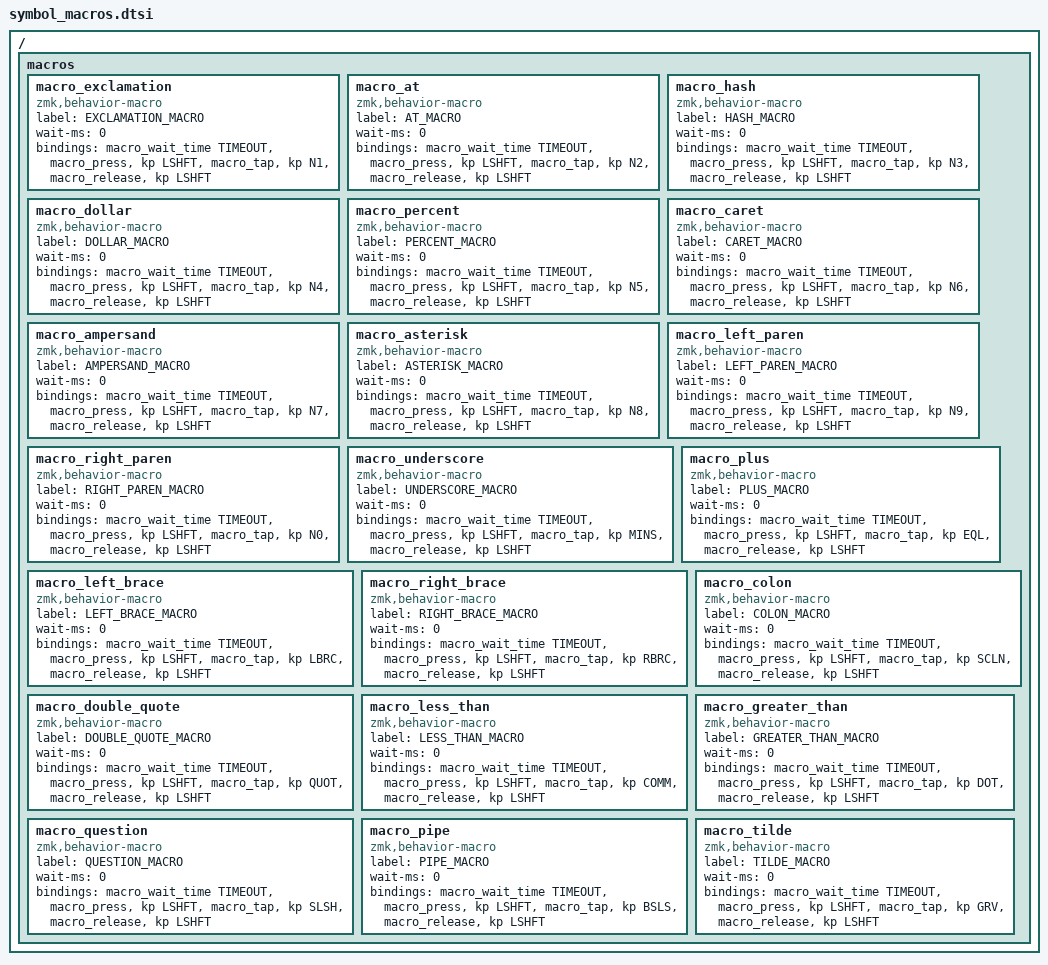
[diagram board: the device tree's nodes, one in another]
/ {
    macros {
        // ! : Shift + 1
        macro_exclamation: macro_exclamation {
            compatible = "zmk,behavior-macro";
            #binding-cells = <0>;
            label = "EXCLAMATION_MACRO";
            wait-ms = <0>; // 必要なら調整
            bindings = 
                <&macro_wait_time TIMEOUT>,
                <&macro_press &kp LSHFT>,
                <&macro_tap &kp N1>,
                <&macro_release &kp LSHFT>;
        };

        // @ : Shift + 2
        macro_at: macro_at {
            compatible = "zmk,behavior-macro";
            #binding-cells = <0>;
            label = "AT_MACRO";
            wait-ms = <0>;
            bindings = 
                <&macro_wait_time TIMEOUT>,
                <&macro_press &kp LSHFT>,
                <&macro_tap &kp N2>,
                <&macro_release &kp LSHFT>;
        };

        // # : Shift + 3
        macro_hash: macro_hash {
            compatible = "zmk,behavior-macro";
            #binding-cells = <0>;
            label = "HASH_MACRO";
            wait-ms = <0>;
            bindings = 
                <&macro_wait_time TIMEOUT>,
                <&macro_press &kp LSHFT>,
                <&macro_tap &kp N3>,
                <&macro_release &kp LSHFT>;
        };

        // $ : Shift + 4
        macro_dollar: macro_dollar {
            compatible = "zmk,behavior-macro";
            #binding-cells = <0>;
            label = "DOLLAR_MACRO";
            wait-ms = <0>;
            bindings = 
                <&macro_wait_time TIMEOUT>,
                <&macro_press &kp LSHFT>,
                <&macro_tap &kp N4>,
                <&macro_release &kp LSHFT>;
        };

        // % : Shift + 5
        macro_percent: macro_percent {
            compatible = "zmk,behavior-macro";
            #binding-cells = <0>;
            label = "PERCENT_MACRO";
            wait-ms = <0>;
            bindings = 
                <&macro_wait_time TIMEOUT>,
                <&macro_press &kp LSHFT>,
                <&macro_tap &kp N5>,
                <&macro_release &kp LSHFT>;
        };

        // ^ : Shift + 6
        macro_caret: macro_caret {
            compatible = "zmk,behavior-macro";
            #binding-cells = <0>;
            label = "CARET_MACRO";
            wait-ms = <0>;
            bindings =
                <&macro_wait_time TIMEOUT>,
                <&macro_press &kp LSHFT>,
                <&macro_tap &kp N6>,
                <&macro_release &kp LSHFT>;
        };

        // & : Shift + 7
        macro_ampersand: macro_ampersand {
            compatible = "zmk,behavior-macro";
            #binding-cells = <0>;
            label = "AMPERSAND_MACRO";
            wait-ms = <0>;
            bindings =
                <&macro_wait_time TIMEOUT>,
                <&macro_press &kp LSHFT>,
                <&macro_tap &kp N7>,
                <&macro_release &kp LSHFT>;
        };

        // * : Shift + 8
        macro_asterisk: macro_asterisk {
            compatible = "zmk,behavior-macro";
            #binding-cells = <0>;
            label = "ASTERISK_MACRO";
            wait-ms = <0>;
            bindings =
                <&macro_wait_time TIMEOUT>,
                <&macro_press &kp LSHFT>,
                <&macro_tap &kp N8>,
                <&macro_release &kp LSHFT>;
        };

        // ( : Shift + 9
        macro_left_paren: macro_left_paren {
            compatible = "zmk,behavior-macro";
            #binding-cells = <0>;
            label = "LEFT_PAREN_MACRO";
            wait-ms = <0>;
            bindings =
                <&macro_wait_time TIMEOUT>,
                <&macro_press &kp LSHFT>,
                <&macro_tap &kp N9>,
                <&macro_release &kp LSHFT>;
        };

        // ) : Shift + 0
        macro_right_paren: macro_right_paren {
            compatible = "zmk,behavior-macro";
            #binding-cells = <0>;
            label = "RIGHT_PAREN_MACRO";
            wait-ms = <0>;
            bindings =
                <&macro_wait_time TIMEOUT>,
                <&macro_press &kp LSHFT>,
                <&macro_tap &kp N0>,
                <&macro_release &kp LSHFT>;
        };

        // _ : Shift + - (MINS)
        macro_underscore: macro_underscore {
            compatible = "zmk,behavior-macro";
            #binding-cells = <0>;
            label = "UNDERSCORE_MACRO";
            wait-ms = <0>;
            bindings =
                <&macro_wait_time TIMEOUT>,
                <&macro_press &kp LSHFT>,
                <&macro_tap &kp MINS>,
                <&macro_release &kp LSHFT>;
        };

        // + : Shift + = (EQL)
        macro_plus: macro_plus {
            compatible = "zmk,behavior-macro";
            #binding-cells = <0>;
            label = "PLUS_MACRO";
            wait-ms = <0>;
            bindings =
                <&macro_wait_time TIMEOUT>,
                <&macro_press &kp LSHFT>,
                <&macro_tap &kp EQL>,
                <&macro_release &kp LSHFT>;
        };

        // { : Shift + [ (LBRC)
        macro_left_brace: macro_left_brace {
            compatible = "zmk,behavior-macro";
            #binding-cells = <0>;
            label = "LEFT_BRACE_MACRO";
            wait-ms = <0>;
            bindings =
                <&macro_wait_time TIMEOUT>,
                <&macro_press &kp LSHFT>,
                <&macro_tap &kp LBRC>,
                <&macro_release &kp LSHFT>;
        };

        // } : Shift + ] (RBRC)
        macro_right_brace: macro_right_brace {
            compatible = "zmk,behavior-macro";
            #binding-cells = <0>;
            label = "RIGHT_BRACE_MACRO";
            wait-ms = <0>;
            bindings =
                <&macro_wait_time TIMEOUT>,
                <&macro_press &kp LSHFT>,
                <&macro_tap &kp RBRC>,
                <&macro_release &kp LSHFT>;
        };

        // : : Shift + ; (SCLN)
        macro_colon: macro_colon {
            compatible = "zmk,behavior-macro";
            #binding-cells = <0>;
            label = "COLON_MACRO";
            wait-ms = <0>;
            bindings =
                <&macro_wait_time TIMEOUT>,
                <&macro_press &kp LSHFT>,
                <&macro_tap &kp SCLN>,
                <&macro_release &kp LSHFT>;
        };

        // " : Shift + ' (QUOT)
        macro_double_quote: macro_double_quote {
            compatible = "zmk,behavior-macro";
            #binding-cells = <0>;
            label = "DOUBLE_QUOTE_MACRO";
            wait-ms = <0>;
            bindings =
                <&macro_wait_time TIMEOUT>,
                <&macro_press &kp LSHFT>,
                <&macro_tap &kp QUOT>,
                <&macro_release &kp LSHFT>;
        };

        // < : Shift + , (COMM)
        macro_less_than: macro_less_than {
            compatible = "zmk,behavior-macro";
            #binding-cells = <0>;
            label = "LESS_THAN_MACRO";
            wait-ms = <0>;
            bindings =
                <&macro_wait_time TIMEOUT>,
                <&macro_press &kp LSHFT>,
                <&macro_tap &kp COMM>,
                <&macro_release &kp LSHFT>;
        };

        // > : Shift + . (DOT)
        macro_greater_than: macro_greater_than {
            compatible = "zmk,behavior-macro";
            #binding-cells = <0>;
            label = "GREATER_THAN_MACRO";
            wait-ms = <0>;
            bindings =
                <&macro_wait_time TIMEOUT>,
                <&macro_press &kp LSHFT>,
                <&macro_tap &kp DOT>,
                <&macro_release &kp LSHFT>;
        };

        // ? : Shift + / (SLSH)
        macro_question: macro_question {
            compatible = "zmk,behavior-macro";
            #binding-cells = <0>;
            label = "QUESTION_MACRO";
            wait-ms = <0>;
            bindings =
                <&macro_wait_time TIMEOUT>,
                <&macro_press &kp LSHFT>,
                <&macro_tap &kp SLSH>,
                <&macro_release &kp LSHFT>;
        };

        // | : Shift + \ (BSLS)
        macro_pipe: macro_pipe {
            compatible = "zmk,behavior-macro";
            #binding-cells = <0>;
            label = "PIPE_MACRO";
            wait-ms = <0>;
            bindings =
                <&macro_wait_time TIMEOUT>,
                <&macro_press &kp LSHFT>,
                <&macro_tap &kp BSLS>,
                <&macro_release &kp LSHFT>;
        };

        // ~ : Shift + ` (GRV)
        macro_tilde: macro_tilde {
            compatible = "zmk,behavior-macro";
            #binding-cells = <0>;
            label = "TILDE_MACRO";
            wait-ms = <0>;
            bindings =
                <&macro_wait_time TIMEOUT>,
                <&macro_press &kp LSHFT>,
                <&macro_tap &kp GRV>,
                <&macro_release &kp LSHFT>;
        };
    };
};
